# STM32G414xx register map
File version: 1.0
Registers are 32-bit, read-write, reset 0x0 unless marked. A register's access mark holds for its fields unless they carry their own. Offsets are from the block's base; [hi:lo] are bit positions; {n}, {i} and the like mark numbered series; 'fields as' and 'values as' point back to an identical list.

## EXTI — External Interrupt/Event Controller
Base 0x40010400
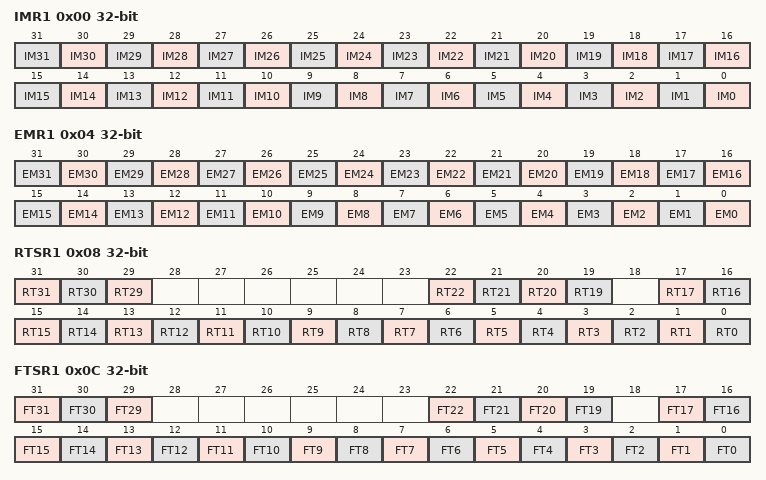
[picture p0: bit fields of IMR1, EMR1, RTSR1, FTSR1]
0x00 IMR1 — EXTI Interrupt mask register 1
  [n] IM{n} (n=0..31) — Interrupt Mask on line {n}
0x04 EMR1 — EXTI Event mask register 1
  [n] EM{n} (n=0..31) — Event Mask on line {n}
0x08 RTSR1 — EXTI Rising trigger selection register 1
  [31] RT31 — Rising trigger event configuration bit of line 31
  [30] RT30 — Rising trigger event configuration bit of line 30
  [29] RT29 — Rising trigger event configuration bit of line 29
  [n] RT{n} (n=19..22) — Rising trigger event configuration bit of line {n}
  [n] RT{n} (n=0..17) — Rising trigger event configuration bit of line {n}
0x0C FTSR1 — EXTI Falling trigger selection register 1
  [31] FT31 — Falling trigger event configuration bit of line 31
  [30] FT30 — Falling trigger event configuration bit of line 30
  [29] FT29 — Falling trigger event configuration bit of line 29
  [n] FT{n} (n=19..22) — Falling trigger event configuration bit of line {n}
  [n] FT{n} (n=0..17) — Falling trigger event configuration bit of line {n}
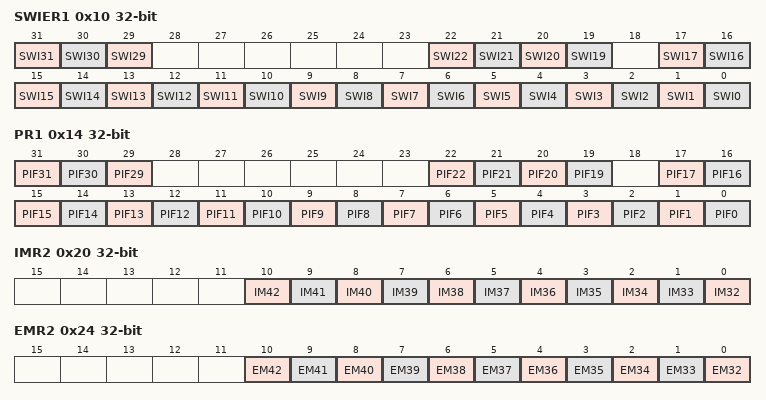
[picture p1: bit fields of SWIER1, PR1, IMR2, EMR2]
0x10 SWIER1 — EXTI Software interrupt event register 1
  [31] SWI31 — Software Interrupt on line 31
  [30] SWI30 — Software Interrupt on line 30
  [29] SWI29 — Software Interrupt on line 29
  [n] SWI{n} (n=19..22) — Software Interrupt on line {n}
  [n] SWI{n} (n=0..17) — Software Interrupt on line {n}
0x14 PR1 — EXTI Pending register 1
  [31] PIF31 — Pending bit for line 31
  [30] PIF30 — Pending bit for line 30
  [29] PIF29 — Pending bit for line 29
  [n] PIF{n} (n=19..22) — Pending bit for line {n}
  [n] PIF{n} (n=0..17) — Pending bit for line {n}
0x20 IMR2 — EXTI Interrupt mask register 2
  [n-32] IM{n} (n=32..42) — Interrupt Mask on line {n}
0x24 EMR2 — EXTI Event mask register 2
  [n-32] EM{n} (n=32..42) — Event Mask on line {n}
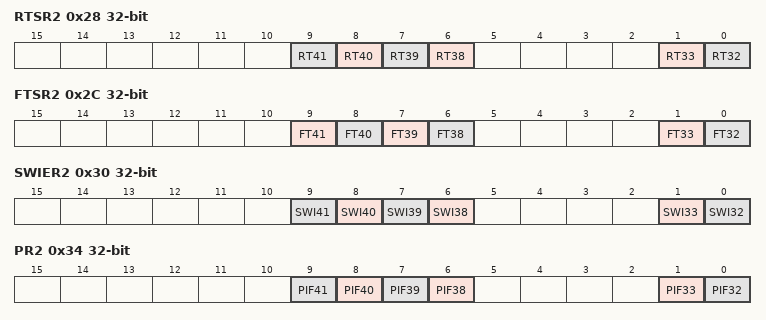
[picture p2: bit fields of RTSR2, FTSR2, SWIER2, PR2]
0x28 RTSR2 — EXTI Rising trigger selection register 2
  [n-32] RT{n} (n=38..41) — Rising trigger event configuration bit of line {n}
  [1] RT33 — Rising trigger event configuration bit of line 33
  [0] RT32 — Rising trigger event configuration bit of line 32
0x2C FTSR2 — EXTI Falling trigger selection register 2
  [9] FT41 — Falling trigger event configuration bit of line 41
  [8] FT40 — Falling trigger event configuration bit of line 40
  [7] FT39 — Falling trigger event configuration bit of line 39
  [6] FT38 — Falling trigger event configuration bit of line 37
  [1] FT33 — Falling trigger event configuration bit of line 33
  [0] FT32 — Falling trigger event configuration bit of line 32
0x30 SWIER2 — EXTI Software interrupt event register 2
  [n-32] SWI{n} (n=38..41) — Software Interrupt on line {n}
  [1] SWI33 — Software Interrupt on line 33
  [0] SWI32 — Software Interrupt on line 32
0x34 PR2 — EXTI Pending register 2
  [n-32] PIF{n} (n=38..41) — Pending bit for line {n}
  [1] PIF33 — Pending bit for line 33
  [0] PIF32 — Pending bit for line 32

## DMA1
Base 0x40020000
Same registers: DMA2 0x40020400
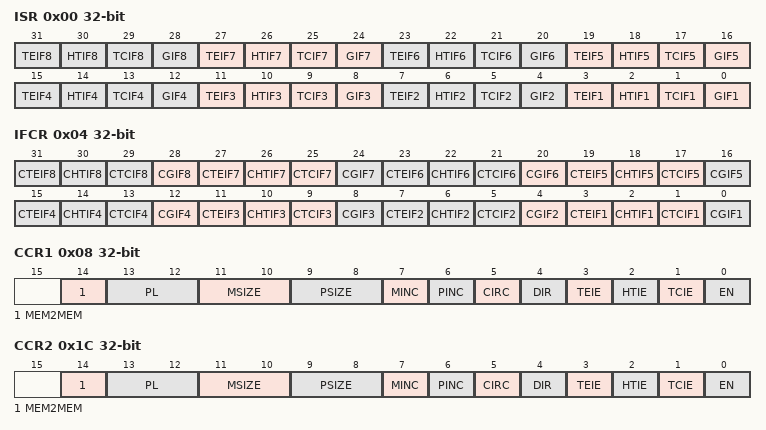
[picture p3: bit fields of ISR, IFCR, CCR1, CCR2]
0x00 ISR — DMA interrupt status register
  [4n-1] TEIF{n} (n=1..8) — Channel {n} Transfer Error flag
  [4n-2] HTIF{n} (n=1..8) — Channel {n} Half Transfer flag
  [4n-3] TCIF{n} (n=1..8) — Channel {n} Transfer Complete flag
  [4n-4] GIF{n} (n=1..8) — Channel {n} Global interrupt flag
0x04 IFCR — DMA interrupt flag clear register
  [4n-1] CTEIF{n} (n=1..8) — Channel {n} Transfer Error clear
  [4n-2] CHTIF{n} (n=1..8) — Channel {n} Half Transfer clear
  [4n-3] CTCIF{n} (n=1..8) — Channel {n} Transfer Complete clear
  [4n-4] CGIF{n} (n=2..8) — Channel {n} Global interrupt clear
  [0] CGIF1 — Channel 1 Global interrupt clearr
0x08 CCR1 — DMA channel x configuration register
  [14] MEM2MEM — Memory to memory mode
  [13:12] PL — PL[1:0] bits(Channel Priority level)
  [11:10] MSIZE — MSIZE[1:0] bits (Memory size)
  [9:8] PSIZE — PSIZE[1:0] bits (Peripheral size)
  [7] MINC — Memory increment mode
  [6] PINC — Peripheral increment mode
  [5] CIRC — Circular mode
  [4] DIR — Data transfer direction
  [3] TEIE — Transfer error interrupt enable
  [2] HTIE — Half Transfer interrupt enable
  [1] TCIE — Transfer complete interrupt enable
  [0] EN — Channel enable
0x0C CNDTR1 — DMA channel x number of data register
  [15:0] NDT — Number of data to Transfer
0x10 CPAR1 — DMA channel x peripheral address register
  [31:0] PA — Peripheral Address
{0x0+0x14*i} CMAR{i} (i=1..8) — DMA channel x memory address register
  [31:0] MA — Memory Address
0x1C CCR2 — DMA channel x configuration register
  fields as CCR1
0x20 CNDTR2 — DMA channel x number of data register
  [15:0] NDT — Number of data to Transfer
0x24 CPAR2 — DMA channel x peripheral address register
  [31:0] PA — Peripheral Address
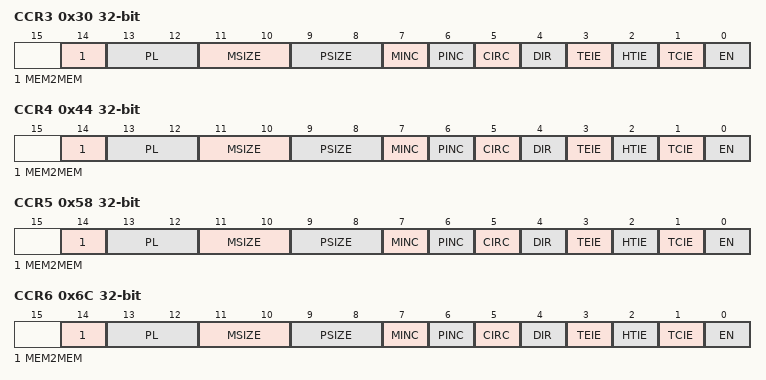
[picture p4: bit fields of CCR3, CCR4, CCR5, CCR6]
0x30 CCR3 — DMA channel x configuration register
  fields as CCR1
0x34 CNDTR3 — DMA channel x number of data register
  [15:0] NDT — Number of data to Transfer
0x38 CPAR3 — DMA channel x peripheral address register
  [31:0] PA — Peripheral Address
0x44 CCR4 — DMA channel x configuration register
  fields as CCR1
0x48 CNDTR4 — DMA channel x number of data register
  [15:0] NDT — Number of data to Transfer
0x4C CPAR4 — DMA channel x peripheral address register
  [31:0] PA — Peripheral Address
0x58 CCR5 — DMA channel x configuration register
  fields as CCR1
0x5C CNDTR5 — DMA channel x number of data register
  [15:0] NDT — Number of data to Transfer
0x60 CPAR5 — DMA channel x peripheral address register
  [31:0] PA — Peripheral Address
0x6C CCR6 — DMA channel x configuration register
  fields as CCR1
0x70 CNDTR6 — DMA channel x number of data register
  [15:0] NDT — Number of data to Transfer
0x74 CPAR6 — DMA channel x peripheral address register
  [31:0] PA — Peripheral Address
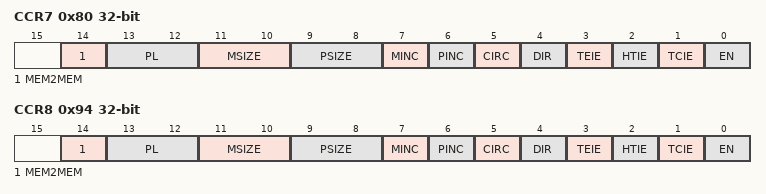
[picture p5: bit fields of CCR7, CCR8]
0x80 CCR7 — DMA channel x configuration register
  fields as CCR1
0x84 CNDTR7 — DMA channel x number of data register
  [15:0] NDT — Number of data to Transfer
0x88 CPAR7 — DMA channel x peripheral address register
  [31:0] PA — Peripheral Address
0x94 CCR8 — DMA channel x configuration register
  fields as CCR1
0x98 CNDTR8 — DMA channel x number of data register
  [15:0] NDT — Number of data to Transfer
0x9C CPAR8 — DMA channel x peripheral address register
  [31:0] PA — Peripheral Address
